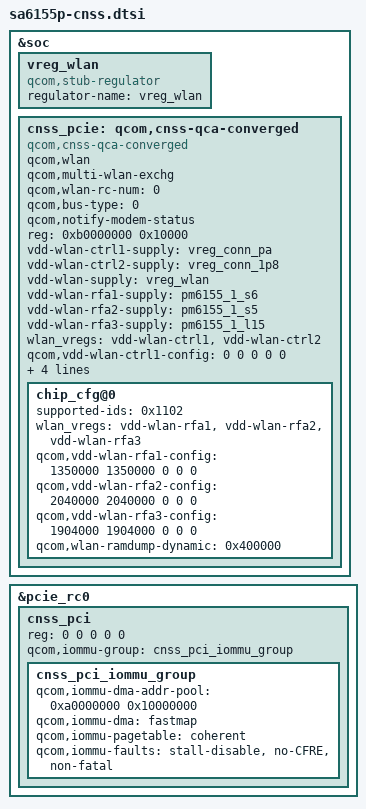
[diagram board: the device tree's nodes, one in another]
#include <dt-bindings/interconnect/qcom,sm6150.h>

&soc {
	vreg_wlan: vreg_wlan {
		compatible = "qcom,stub-regulator";
		regulator-name = "vreg_wlan";
	};

	cnss_pcie: qcom,cnss-qca-converged {
		compatible = "qcom,cnss-qca-converged";
		qcom,wlan;
		qcom,multi-wlan-exchg;
		qcom,wlan-rc-num = <0>;
		qcom,bus-type=<0>;
		qcom,notify-modem-status;

		reg = <0xb0000000 0x10000>;
		reg-names = "smmu_iova_ipa";

		vdd-wlan-ctrl1-supply = <&vreg_conn_pa>;
		vdd-wlan-ctrl2-supply = <&vreg_conn_1p8>;
		vdd-wlan-supply = <&vreg_wlan>;
		vdd-wlan-rfa1-supply = <&pm6155_1_s6>;
		vdd-wlan-rfa2-supply = <&pm6155_1_s5>;
		vdd-wlan-rfa3-supply = <&pm6155_1_l15>;

		wlan_vregs = "vdd-wlan-ctrl1", "vdd-wlan-ctrl2";
		qcom,vdd-wlan-ctrl1-config = <0 0 0 0 0>;
		qcom,vdd-wlan-ctrl2-config = <0 0 0 0 0>;
		wlan-en-gpio = <&tlmm 98 0>;
		pinctrl-names = "wlan_en_active", "wlan_en_sleep";
		pinctrl-0 = <&cnss_wlan_en_active>;
		pinctrl-1 = <&cnss_wlan_en_sleep>;

		chip_cfg@0 {
			supported-ids = <0x1102>;
			wlan_vregs = "vdd-wlan-rfa1", "vdd-wlan-rfa2",
				   "vdd-wlan-rfa3";
			qcom,vdd-wlan-rfa1-config = <1350000 1350000 0 0 0>;
			qcom,vdd-wlan-rfa2-config = <2040000 2040000 0 0 0>;
			qcom,vdd-wlan-rfa3-config = <1904000 1904000 0 0 0>;

			qcom,wlan-ramdump-dynamic = <0x400000>;
		};
	};
};


&pcie_rc0 {
	#address-cells = <5>;
	#size-cells = <0>;
	cnss_pci: cnss_pci {
		reg = <0 0 0 0 0>;
		qcom,iommu-group = <&cnss_pci_iommu_group>;

		#address-cells = <1>;
		#size-cells = <1>;

		cnss_pci_iommu_group: cnss_pci_iommu_group {
		qcom,iommu-dma-addr-pool = <0xa0000000 0x10000000>;
		qcom,iommu-dma = "fastmap";
		qcom,iommu-pagetable = "coherent";
		qcom,iommu-faults = "stall-disable", "no-CFRE",
			 "non-fatal";
		};
	};
};

